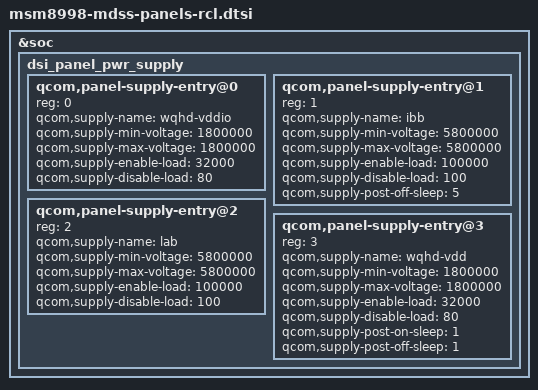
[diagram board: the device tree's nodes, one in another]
/* Copyright (c) 2016-2018, The Linux Foundation. All rights reserved.
 *
 * This program is free software; you can redistribute it and/or modify
 * it under the terms of the GNU General Public License version 2 and
 * only version 2 as published by the Free Software Foundation.
 *
 * This program is distributed in the hope that it will be useful,
 * but WITHOUT ANY WARRANTY; without even the implied warranty of
 * MERCHANTABILITY or FITNESS FOR A PARTICULAR PURPOSE.  See the
 * GNU General Public License for more details.
 */

#include "dsi-panel-nt36830-wqhd-dualmipi-cmd.dtsi"
#include "dsi-panel-nt36830-wqhd-dualmipi-video.dtsi"

&soc {
	dsi_panel_pwr_supply: dsi_panel_pwr_supply {
		#address-cells = <1>;
		#size-cells = <0>;

		qcom,panel-supply-entry@0 {
			reg = <0>;
			qcom,supply-name = "wqhd-vddio";
			qcom,supply-min-voltage = <1800000>;
			qcom,supply-max-voltage = <1800000>;
			qcom,supply-enable-load = <32000>;
			qcom,supply-disable-load = <80>;
		};

		qcom,panel-supply-entry@1 {
			reg = <1>;
			qcom,supply-name = "ibb";
			qcom,supply-min-voltage = <5800000>;
			qcom,supply-max-voltage = <5800000>;
			qcom,supply-enable-load = <100000>;
			qcom,supply-disable-load = <100>;
			qcom,supply-post-off-sleep = <5>;
		};

		qcom,panel-supply-entry@2 {
			reg = <2>;
			qcom,supply-name = "lab";
			qcom,supply-min-voltage = <5800000>;
			qcom,supply-max-voltage = <5800000>;
			qcom,supply-enable-load = <100000>;
			qcom,supply-disable-load = <100>;
		};

		qcom,panel-supply-entry@3 {
			reg = <3>;
			qcom,supply-name = "wqhd-vdd";
			qcom,supply-min-voltage = <1800000>;
			qcom,supply-max-voltage = <1800000>;
			qcom,supply-enable-load = <32000>;
			qcom,supply-disable-load = <80>;
			qcom,supply-post-on-sleep = <1>;
			qcom,supply-post-off-sleep = <1>;
		};
	};
};
